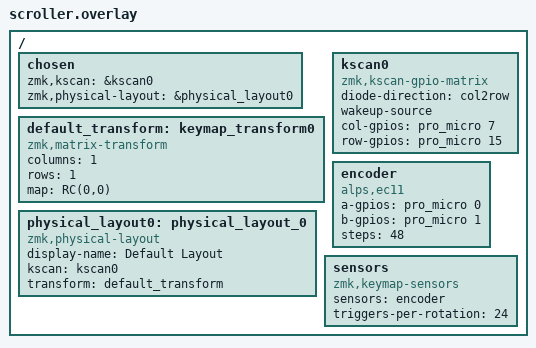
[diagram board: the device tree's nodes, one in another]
#include <dt-bindings/zmk/matrix_transform.h> // Put this with the other includes at the top of your overlay

/ {
    chosen {
        zmk,kscan = &kscan0;
        zmk,physical-layout = &physical_layout0;
    };
};

/ {
    default_transform: keymap_transform0 {
        compatible = "zmk,matrix-transform";
        columns = <1>;
        rows = <1>;
        map = <
            RC(0,0)
        >;
    };
};

/ {
    kscan0: kscan0 {
        compatible = "zmk,kscan-gpio-matrix";
        diode-direction = "col2row";
        wakeup-source;

        col-gpios
            = <&pro_micro 7 GPIO_ACTIVE_HIGH>
            ;

        row-gpios
            = <&pro_micro 15 (GPIO_ACTIVE_HIGH | GPIO_PULL_DOWN)>
            ;
    };
};

/ {
    physical_layout0: physical_layout_0 {
        compatible = "zmk,physical-layout";
        display-name = "Default Layout";
        kscan = <&kscan0>;
        transform = <&default_transform>;
    };
};

/ {
    encoder: encoder {
        compatible = "alps,ec11";
        a-gpios = <&pro_micro 0 (GPIO_ACTIVE_HIGH | GPIO_PULL_UP)>;
        b-gpios = <&pro_micro 1 (GPIO_ACTIVE_HIGH | GPIO_PULL_UP)>;
        steps = <48>;
        status = "okay";
    };

    sensors: sensors {
        compatible = "zmk,keymap-sensors";
        sensors = <&encoder>;
        triggers-per-rotation = <24>;
    };
};
